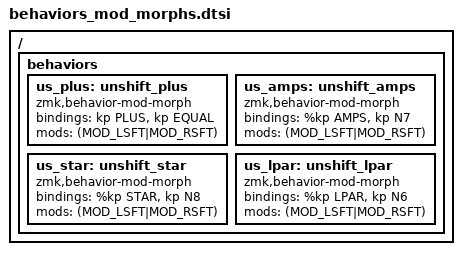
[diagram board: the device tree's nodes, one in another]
/ {
    behaviors {
        // Unshift -- most of these are to be able to run 
        /omit-if-no-ref/ us_plus: unshift_plus {
            compatible = "zmk,behavior-mod-morph";
            #binding-cells = <0>;
            bindings = <&kp PLUS>, <&kp EQUAL>;
            mods = <(MOD_LSFT|MOD_RSFT)>;
        };
        /omit-if-no-ref/ us_amps: unshift_amps {
            compatible = "zmk,behavior-mod-morph";
            #binding-cells = <0>;
            bindings = <%kp AMPS>, <&kp N7>;
            mods = <(MOD_LSFT|MOD_RSFT)>;
        }; 
        /omit-if-no-ref/ us_star: unshift_star {
            compatible = "zmk,behavior-mod-morph";
            #binding-cells = <0>;
            bindings = <%kp STAR>, <&kp N8>;
            mods = <(MOD_LSFT|MOD_RSFT)>;
        };
        /omit-if-no-ref/ us_lpar: unshift_lpar {
            compatible = "zmk,behavior-mod-morph";
            #binding-cells = <0>;
            bindings = <%kp LPAR>, <&kp N6>;
            mods = <(MOD_LSFT|MOD_RSFT)>;
        };
    };
};
